# TM4C129ENCPDT register map
File version: 1.0
CPU: CORTEX_M4 1.0, other endian, MPU, FPU, 3 interrupt priority bits
Registers are 32-bit, read-write, reset 0x0 unless marked. A register's access mark holds for its fields unless they carry their own. Offsets are from the block's base; [hi:lo] are bit positions; {n}, {i} and the like mark numbered series.

## QEI0 — QEI register offsets
Base 0x4002C000
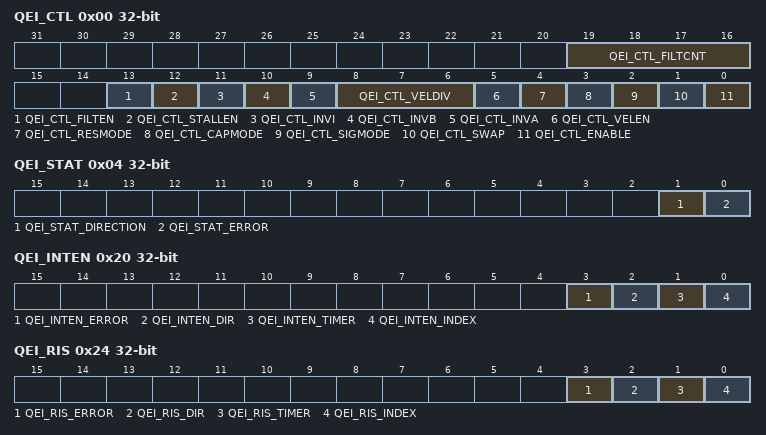
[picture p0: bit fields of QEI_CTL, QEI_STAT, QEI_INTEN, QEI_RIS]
0x00 QEI_CTL — QEI Control
  [19:16] QEI_CTL_FILTCNT — [19:16] Input Filter Prescale Count
  [13] QEI_CTL_FILTEN — [13:13] Enable Input Filter
  [12] QEI_CTL_STALLEN — [12:12] Stall QEI
  [11] QEI_CTL_INVI — [11:11] Invert Index Pulse
  [10] QEI_CTL_INVB — [10:10] Invert PhB
  [9] QEI_CTL_INVA — [9:9] Invert PhA
  [8:6] QEI_CTL_VELDIV — [8:6] Predivide Velocity
    0=QEI clock /1; 64=QEI clock /2; 128=QEI clock /4; 192=QEI clock /8; 0x100=QEI clock /16; 0x140=QEI clock /32; 0x180=QEI clock /64; 0x1C0=QEI clock /128
  [5] QEI_CTL_VELEN — [5:5] Capture Velocity
  [4] QEI_CTL_RESMODE — [4:4] Reset Mode
  [3] QEI_CTL_CAPMODE — [3:3] Capture Mode
  [2] QEI_CTL_SIGMODE — [2:2] Signal Mode
  [1] QEI_CTL_SWAP — [1:1] Swap Signals
  [0] QEI_CTL_ENABLE — [0:0] Enable QEI
0x04 QEI_STAT — QEI Status
  [1] QEI_STAT_DIRECTION — [1:1] Direction of Rotation
  [0] QEI_STAT_ERROR — [0:0] Error Detected
0x08 QEI_POS — QEI Position
  [31:0] QEI_POS — [31:0] Current Position Integrator Value
0x0C QEI_MAXPOS — QEI Maximum Position
  [31:0] QEI_MAXPOS — [31:0] Maximum Position Integrator Value
0x10 QEI_LOAD — QEI Timer Load
  [31:0] QEI_LOAD — [31:0] Velocity Timer Load Value
0x14 QEI_TIME — QEI Timer
  [31:0] QEI_TIME — [31:0] Velocity Timer Current Value
0x18 QEI_COUNT — QEI Velocity Counter
  [31:0] QEI_COUNT — [31:0] Velocity Pulse Count
0x1C QEI_SPEED — QEI Velocity
  [31:0] QEI_SPEED — [31:0] Velocity
0x20 QEI_INTEN — QEI Interrupt Enable
  [3] QEI_INTEN_ERROR — [3:3] Phase Error Interrupt Enable
  [2] QEI_INTEN_DIR — [2:2] Direction Change Interrupt Enable
  [1] QEI_INTEN_TIMER — [1:1] Timer Expires Interrupt Enable
  [0] QEI_INTEN_INDEX — [0:0] Index Pulse Detected Interrupt Enable
0x24 QEI_RIS — QEI Raw Interrupt Status
  [3] QEI_RIS_ERROR — [3:3] Phase Error Detected
  [2] QEI_RIS_DIR — [2:2] Direction Change Detected
  [1] QEI_RIS_TIMER — [1:1] Velocity Timer Expired
  [0] QEI_RIS_INDEX — [0:0] Index Pulse Asserted
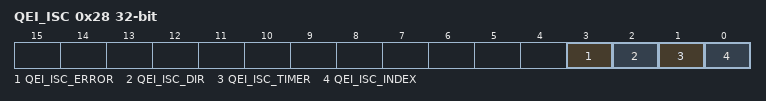
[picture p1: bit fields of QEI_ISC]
0x28 QEI_ISC — QEI Interrupt Status and Clear
  [3] QEI_ISC_ERROR — [3:3] Phase Error Interrupt
  [2] QEI_ISC_DIR — [2:2] Direction Change Interrupt
  [1] QEI_ISC_TIMER — [1:1] Velocity Timer Expired Interrupt
  [0] QEI_ISC_INDEX — [0:0] Index Pulse Interrupt

## COMP — Comparator register offsets
Base 0x4003C000
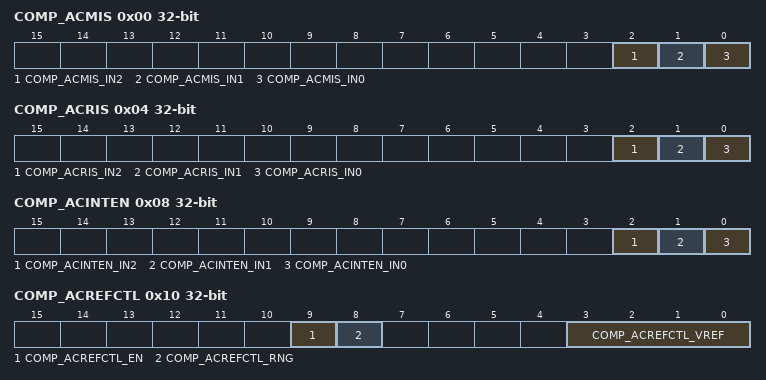
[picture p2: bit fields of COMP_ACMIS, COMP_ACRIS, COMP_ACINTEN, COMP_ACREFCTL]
0x00 COMP_ACMIS — Analog Comparator Masked Interrupt Status
  [2] COMP_ACMIS_IN2 — [2:2] Comparator 2 Masked Interrupt Status
  [1] COMP_ACMIS_IN1 — [1:1] Comparator 1 Masked Interrupt Status
  [0] COMP_ACMIS_IN0 — [0:0] Comparator 0 Masked Interrupt Status
0x04 COMP_ACRIS — Analog Comparator Raw Interrupt Status
  [2] COMP_ACRIS_IN2 — [2:2] Comparator 2 Interrupt Status
  [1] COMP_ACRIS_IN1 — [1:1] Comparator 1 Interrupt Status
  [0] COMP_ACRIS_IN0 — [0:0] Comparator 0 Interrupt Status
0x08 COMP_ACINTEN — Analog Comparator Interrupt Enable
  [2] COMP_ACINTEN_IN2 — [2:2] Comparator 2 Interrupt Enable
  [1] COMP_ACINTEN_IN1 — [1:1] Comparator 1 Interrupt Enable
  [0] COMP_ACINTEN_IN0 — [0:0] Comparator 0 Interrupt Enable
0x10 COMP_ACREFCTL — Analog Comparator Reference Voltage Control
  [9] COMP_ACREFCTL_EN — [9:9] Resistor Ladder Enable
  [8] COMP_ACREFCTL_RNG — [8:8] Resistor Ladder Range
  [3:0] COMP_ACREFCTL_VREF — [3:0] Resistor Ladder Voltage Ref
{0x20+0x20*i} COMP_ACSTAT{i} (i=0..2) — Analog Comparator Status {i}
  [1] COMP_ACSTAT{i}_OVAL — [1:1] Comparator Output Value
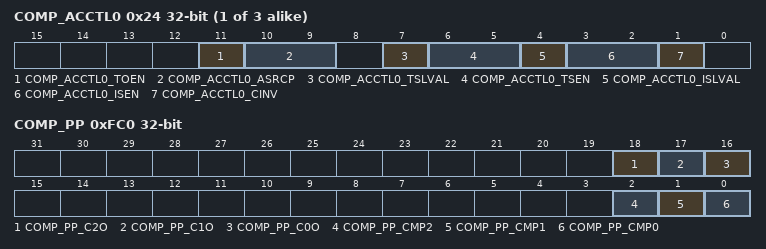
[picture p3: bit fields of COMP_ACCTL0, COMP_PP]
{0x24+0x20*i} COMP_ACCTL{i} (i=0..2) — Analog Comparator Control {i}
  [11] COMP_ACCTL{i}_TOEN — [11:11] Trigger Output Enable
  [10:9] COMP_ACCTL{i}_ASRCP — [10:9] Analog Source Positive
    0=COMP_ACCTL{i}_ASRCP_PIN (Pin value of Cn+); 0x200=COMP_ACCTL{i}_ASRCP_PIN0 (Pin value of C0+); 0x400=COMP_ACCTL{i}_ASRCP_REF (Internal voltage reference)
  [7] COMP_ACCTL{i}_TSLVAL — [7:7] Trigger Sense Level Value
  [6:5] COMP_ACCTL{i}_TSEN — [6:5] Trigger Sense
    0=COMP_ACCTL{i}_TSEN_LEVEL (Level sense, see TSLVAL); 32=COMP_ACCTL{i}_TSEN_FALL (Falling edge); 64=COMP_ACCTL{i}_TSEN_RISE (Rising edge); 96=COMP_ACCTL{i}_TSEN_BOTH (Either edge)
  [4] COMP_ACCTL{i}_ISLVAL — [4:4] Interrupt Sense Level Value
  [3:2] COMP_ACCTL{i}_ISEN — [3:2] Interrupt Sense
    0=COMP_ACCTL{i}_ISEN_LEVEL (Level sense, see ISLVAL); 4=COMP_ACCTL{i}_ISEN_FALL (Falling edge); 8=COMP_ACCTL{i}_ISEN_RISE (Rising edge); 12=COMP_ACCTL{i}_ISEN_BOTH (Either edge)
  [1] COMP_ACCTL{i}_CINV — [1:1] Comparator Output Invert
0xFC0 COMP_PP — Analog Comparator Peripheral Properties
  [18] COMP_PP_C2O — [18:18] Comparator Output 2 Present
  [17] COMP_PP_C1O — [17:17] Comparator Output 1 Present
  [16] COMP_PP_C0O — [16:16] Comparator Output 0 Present
  [2] COMP_PP_CMP2 — [2:2] Comparator 2 Present
  [1] COMP_PP_CMP1 — [1:1] Comparator 1 Present
  [0] COMP_PP_CMP0 — [0:0] Comparator 0 Present
